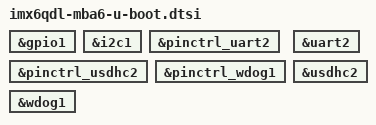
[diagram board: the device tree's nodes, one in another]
// SPDX-License-Identifier: (GPL-2.0-or-later OR MIT)
/*
 * Copyright (c) 2023-2026 TQ-Systems GmbH <u-boot@ew.tq-group.com>,
 * D-82229 Seefeld, Germany.
 * Author: Markus Niebel
 */

#include "imx6qdl-tqma6-u-boot.dtsi"

&gpio1 {
	bootph-pre-ram;
};

&i2c1 {
	bootph-pre-ram;
};

&pinctrl_uart2 {
	bootph-pre-ram;
};

&pinctrl_usdhc2 {
	bootph-pre-ram;
};

&pinctrl_wdog1{
	bootph-pre-ram;
};

&uart2 {
	bootph-pre-ram;
};

&usdhc2 {
	bootph-pre-ram;
};

&wdog1 {
	bootph-pre-ram;
};
